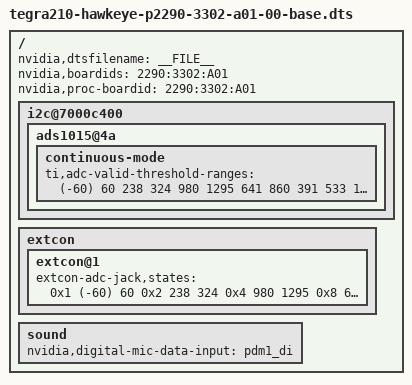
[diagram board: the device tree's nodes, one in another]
/*
 * Hawkeye P2290 A01 board.
 *	NVPN: 699-82290-3302-001
 *	variant: WWAN_3GB_F0_EVT
 *	SKU: 3302
 *	assembly version: TM671D & Wi-Fi + LTE
 *	LPDDR4 capacity: 3 GB
 *	optional features: no NFC + no sensor hub + no barometer
 *	manufacturing phase : EVT
 *
 * Copyright (c) 2015-2016, NVIDIA CORPORATION.  All rights reserved.
 *
 * This program is free software; you can redistribute it and/or modify
 * it under the terms of the GNU General Public License as published by
 * the Free Software Foundation; version 2 of the License.
 *
 * This program is distributed in the hope that it will be useful, but WITHOUT
 * ANY WARRANTY; without even the implied warranty of MERCHANTABILITY or
 * FITNESS FOR A PARTICULAR PURPOSE.  See the GNU General Public License for
 * more details.
 */

#include "tegra210-hawkeye-p2290-a00-00-base.dts"
#include "tegra210-platforms/tegra210-sysedp.dtsi"

/ {
	nvidia,dtsfilename = __FILE__;
	nvidia,boardids = "2290:3302:A01";
	nvidia,proc-boardid = "2290:3302:A01";

	i2c@7000c400 {
		ads1015@4a {
			continuous-mode {
				ti,adc-valid-threshold-ranges= <(-60)     60
							238    324
							980   1295
							641   860
							391   533
							1389  2047>;
			};
		};
	};

	extcon {
		extcon@1 {
			extcon-adc-jack,states = <0x1   (-60)      60
						0x2     238      324
						0x4     980     1295
						0x8     641     860
						0x10    391     533>;
		};
	};

	sound {
		nvidia,digital-mic-data-input = "pdm1_di";
	};
};
